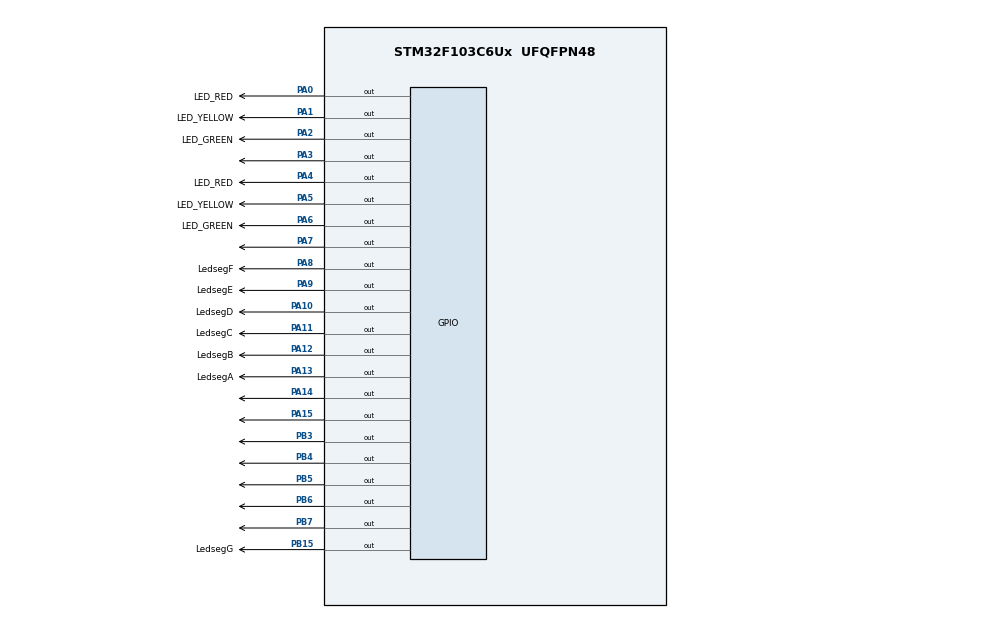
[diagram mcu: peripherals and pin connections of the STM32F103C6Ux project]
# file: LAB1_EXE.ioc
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Mcu.Family=STM32F1
Mcu.Name=STM32F103C6Ux
Mcu.Package=UFQFPN48
NVIC.PriorityGroup=NVIC_PRIORITYGROUP_4
PA0-WKUP.GPIO_Label=LED_RED
PA0-WKUP.Signal=GPIO_Output
PA1.GPIO_Label=LED_YELLOW
PA1.Signal=GPIO_Output
PA10.GPIO_Label=LedsegD
PA10.Signal=GPIO_Output
PA11.GPIO_Label=LedsegC
PA11.Signal=GPIO_Output
PA12.GPIO_Label=LedsegB
PA12.Signal=GPIO_Output
PA13.GPIO_Label=LedsegA
PA13.Signal=GPIO_Output
PA14.Signal=GPIO_Output
PA15.Signal=GPIO_Output
PA2.GPIO_Label=LED_GREEN
PA2.Signal=GPIO_Output
PA3.Signal=GPIO_Output
PA4.GPIO_Label=LED_RED
PA4.Signal=GPIO_Output
PA5.GPIO_Label=LED_YELLOW
PA5.Signal=GPIO_Output
PA6.GPIO_Label=LED_GREEN
PA6.Signal=GPIO_Output
PA7.Signal=GPIO_Output
PA8.GPIO_Label=LedsegF
PA8.Signal=GPIO_Output
PA9.GPIO_Label=LedsegE
PA9.Signal=GPIO_Output
PB15.GPIO_Label=LedsegG
PB15.Signal=GPIO_Output
PB3.Signal=GPIO_Output
PB4.Signal=GPIO_Output
PB5.Signal=GPIO_Output
PB6.Signal=GPIO_Output
PB7.Signal=GPIO_Output
ProjectManager.HeapSize=0x200
ProjectManager.StackSize=0x400
ProjectManager.TargetToolchain=STM32CubeIDE
RCC.APB1Freq_Value=8000000
RCC.APB2Freq_Value=8000000
VP_SYS_VS_ND.Mode=No_Debug
board=custom

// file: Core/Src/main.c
/* USER CODE BEGIN Header */
/**
  ******************************************************************************
  * @file           : main.c
  * @brief          : Main program body
  ******************************************************************************
  * @attention
  *
  * <h2><center>&copy; Copyright (c) 2023 STMicroelectronics.
  * All rights reserved.</center></h2>
  *
  * This software component is licensed by ST under BSD 3-Clause license,
  * the "License"; You may not use this file except in compliance with the
  * License. You may obtain a copy of the License at:
  *                        opensource.org/licenses/BSD-3-Clause
  *
  ******************************************************************************
  */
/* USER CODE END Header */
#include "main.h"
#include "FuncClock.h"

void SystemClock_Config(void);
static void MX_GPIO_Init(void);

int main(void)
{

  /* MCU Configuration--------------------------------------------------------*/

  /* Reset of all peripherals, Initializes the Flash interface and the Systick. */
  HAL_Init();

  /* Configure the system clock */
  SystemClock_Config();

  /* Initialize all configured peripherals */
  MX_GPIO_Init();

  /* Infinite loop */
  /* USER CODE BEGIN WHILE */
  int counterSec =0;
  int counterMin =0;
  int counterHour =0;

  int ledSec = 0;
  int ledMin =0;
  int ledHour =0;
  clearAllClock();
  setNumberOnClock(0);

  while (1)
  {
    /* USER CODE END WHILE */
	  if(counterSec ==60)
	  {
			if(counterSec /5 -1 != ledMin && counterSec /5 -1 != ledHour)
			{
				clearNumberOnClock(counterSec /5 -1 );
			}
			setNumberOnClock(0);
		  counterSec=0;
		  ledSec =0;
		  counterMin++;
		  if(counterMin ==60)  //Min run
		  {
			  if(counterMin/5-1 != ledSec && counterMin/5 -1 != ledHour)
			  {
				  clearNumberOnClock(counterMin/5-1);
			  }
			  setNumberOnClock(0);
			  counterMin =0;
			  ledMin =0;
			  counterHour++;
			  if(counterHour ==12)
			  {
				  clearAllClock();
				  setNumberOnClock(0);
				  counterSec =0;
				  counterMin =0;
				  counterHour =0;

				  ledSec = 0;
				  ledMin =0;
				  ledHour =0;

			  }
			  else if(counterHour -1 != ledSec && counterHour-1 != ledMin)
			  {
				  clearNumberOnClock(counterHour-1);
			  }
			  setNumberOnClock(counterHour);
			  ledHour = counterHour;
		  }
		  else if(counterMin%5 ==0)
		  {
			  if(counterMin/5-1 != ledSec && counterMin/5 -1 != ledHour)
			  {
				  clearNumberOnClock(counterMin/5-1);
			  }
			  setNumberOnClock(counterMin /5 );
			  ledMin = counterMin/5;
		  }
	  }
	  else if (counterSec % 5 ==0) //sec run
	  {

		if(counterSec /5 -1 != ledMin && counterSec /5 -1 != ledHour)
		{
			clearNumberOnClock(counterSec /5 -1);
		}
		setNumberOnClock(counterSec/5);
		ledSec= counterSec/5;
	  }

	  HAL_Delay(1);
	  counterSec++;
  }
}

void SystemClock_Config(void)
{
  RCC_OscInitTypeDef RCC_OscInitStruct = {0};
  RCC_ClkInitTypeDef RCC_ClkInitStruct = {0};

  /** Initializes the RCC Oscillators according to the specified parameters
  * in the RCC_OscInitTypeDef structure.
  */
  RCC_OscInitStruct.OscillatorType = RCC_OSCILLATORTYPE_HSI;
  RCC_OscInitStruct.HSIState = RCC_HSI_ON;
  RCC_OscInitStruct.HSICalibrationValue = RCC_HSICALIBRATION_DEFAULT;
  RCC_OscInitStruct.PLL.PLLState = RCC_PLL_NONE;
  if (HAL_RCC_OscConfig(&RCC_OscInitStruct) != HAL_OK)
  {
    Error_Handler();
  }
  /** Initializes the CPU, AHB and APB buses clocks
  */
  RCC_ClkInitStruct.ClockType = RCC_CLOCKTYPE_HCLK|RCC_CLOCKTYPE_SYSCLK
                              |RCC_CLOCKTYPE_PCLK1|RCC_CLOCKTYPE_PCLK2;
  RCC_ClkInitStruct.SYSCLKSource = RCC_SYSCLKSOURCE_HSI;
  RCC_ClkInitStruct.AHBCLKDivider = RCC_SYSCLK_DIV1;
  RCC_ClkInitStruct.APB1CLKDivider = RCC_HCLK_DIV1;
  RCC_ClkInitStruct.APB2CLKDivider = RCC_HCLK_DIV1;

  if (HAL_RCC_ClockConfig(&RCC_ClkInitStruct, FLASH_LATENCY_0) != HAL_OK)
  {
    Error_Handler();
  }
}

static void MX_GPIO_Init(void)
{
  GPIO_InitTypeDef GPIO_InitStruct = {0};

  /* GPIO Ports Clock Enable */
  __HAL_RCC_GPIOA_CLK_ENABLE();
  __HAL_RCC_GPIOB_CLK_ENABLE();

  /*Configure GPIO pin Output Level */
  HAL_GPIO_WritePin(GPIOA, LED_RED_Pin|LED_YELLOW_Pin|LED_GREEN_Pin|GPIO_PIN_3
                          |LED_REDA4_Pin|LED_YELLOWA5_Pin|LED_GREENA6_Pin|GPIO_PIN_7
                          |LedsegF_Pin|LedsegE_Pin|LedsegD_Pin|LedsegC_Pin
                          |LedsegB_Pin|LedsegA_Pin|GPIO_PIN_14|GPIO_PIN_15, GPIO_PIN_RESET);

  /*Configure GPIO pin Output Level */
  HAL_GPIO_WritePin(GPIOB, LedsegG_Pin|GPIO_PIN_3|GPIO_PIN_4|GPIO_PIN_5
                          |GPIO_PIN_6|GPIO_PIN_7, GPIO_PIN_RESET);

  /*Configure GPIO pins : LED_RED_Pin LED_YELLOW_Pin LED_GREEN_Pin PA3
                           LED_REDA4_Pin LED_YELLOWA5_Pin LED_GREENA6_Pin PA7
                           LedsegF_Pin LedsegE_Pin LedsegD_Pin LedsegC_Pin
                           LedsegB_Pin LedsegA_Pin PA14 PA15 */
  GPIO_InitStruct.Pin = LED_RED_Pin|LED_YELLOW_Pin|LED_GREEN_Pin|GPIO_PIN_3
                          |LED_REDA4_Pin|LED_YELLOWA5_Pin|LED_GREENA6_Pin|GPIO_PIN_7
                          |LedsegF_Pin|LedsegE_Pin|LedsegD_Pin|LedsegC_Pin
                          |LedsegB_Pin|LedsegA_Pin|GPIO_PIN_14|GPIO_PIN_15;
  GPIO_InitStruct.Mode = GPIO_MODE_OUTPUT_PP;
  GPIO_InitStruct.Pull = GPIO_NOPULL;
  GPIO_InitStruct.Speed = GPIO_SPEED_FREQ_LOW;
  HAL_GPIO_Init(GPIOA, &GPIO_InitStruct);

  /*Configure GPIO pins : LedsegG_Pin PB3 PB4 PB5
                           PB6 PB7 */
  GPIO_InitStruct.Pin = LedsegG_Pin|GPIO_PIN_3|GPIO_PIN_4|GPIO_PIN_5
                          |GPIO_PIN_6|GPIO_PIN_7;
  GPIO_InitStruct.Mode = GPIO_MODE_OUTPUT_PP;
  GPIO_InitStruct.Pull = GPIO_NOPULL;
  GPIO_InitStruct.Speed = GPIO_SPEED_FREQ_LOW;
  HAL_GPIO_Init(GPIOB, &GPIO_InitStruct);

}

void Error_Handler(void)
{
  __disable_irq();
  while (1)
  {
  }
}

/************************ (C) COPYRIGHT STMicroelectronics *****END OF FILE****/
